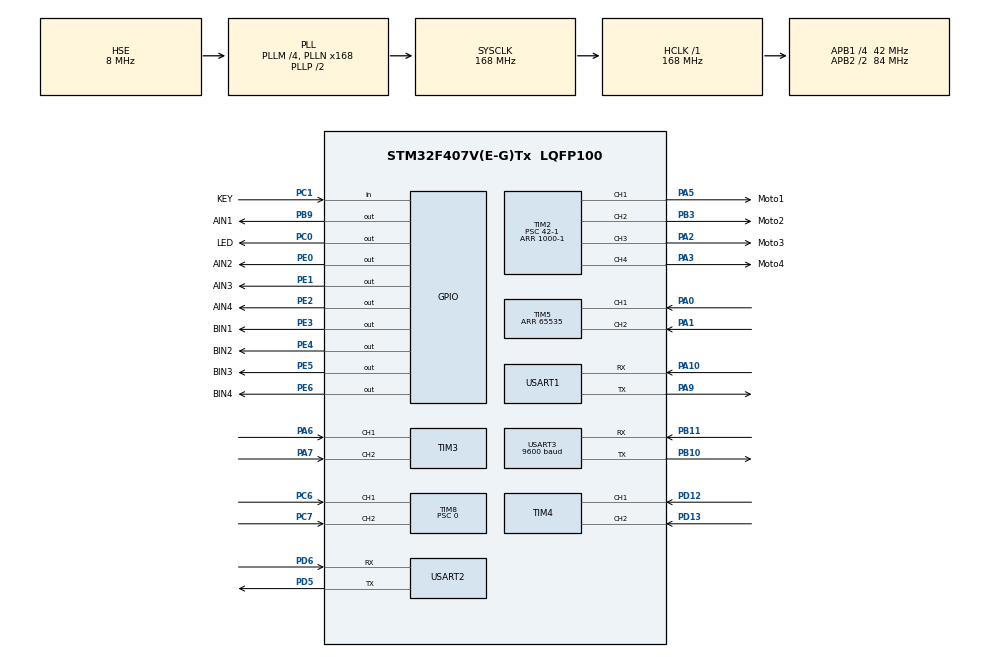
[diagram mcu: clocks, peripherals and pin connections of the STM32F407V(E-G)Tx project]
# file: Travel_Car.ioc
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Mcu.Family=STM32F4
Mcu.Name=STM32F407V(E-G)Tx
Mcu.Package=LQFP100
NVIC.PriorityGroup=NVIC_PRIORITYGROUP_4
NVIC.TIM1_UP_TIM10_IRQn=true\:0\:0\:false\:false\:true\:true\:true
NVIC.TIM2_IRQn=true\:0\:0\:false\:false\:true\:true\:true
NVIC.TIM3_IRQn=true\:0\:0\:false\:false\:true\:true\:true
NVIC.TIM4_IRQn=true\:0\:0\:false\:false\:true\:true\:true
NVIC.TIM5_IRQn=true\:0\:0\:false\:false\:true\:true\:true
NVIC.TIM8_UP_TIM13_IRQn=true\:0\:0\:false\:false\:true\:true\:true
NVIC.USART1_IRQn=true\:0\:0\:false\:false\:true\:true\:true
NVIC.USART2_IRQn=true\:0\:0\:false\:false\:true\:true\:true
NVIC.USART3_IRQn=true\:0\:0\:false\:false\:true\:true\:true
PA0-WKUP.Signal=S_TIM5_CH1
PA1.Signal=S_TIM5_CH2
PA10.Mode=Asynchronous
PA10.Signal=USART1_RX
PA13.Mode=Serial_Wire
PA13.Signal=SYS_JTMS-SWDIO
PA14.Mode=Serial_Wire
PA14.Signal=SYS_JTCK-SWCLK
PA2.GPIO_Label=Moto3
PA2.Signal=S_TIM2_CH3
PA3.GPIO_Label=Moto4
PA3.Signal=S_TIM2_CH4
PA5.GPIO_Label=Moto1
PA5.Signal=S_TIM2_CH1_ETR
PA6.Signal=S_TIM3_CH1
PA7.Signal=S_TIM3_CH2
PA9.Mode=Asynchronous
PA9.Signal=USART1_TX
PB10.Mode=Asynchronous
PB10.Signal=USART3_TX
PB11.Mode=Asynchronous
PB11.Signal=USART3_RX
PB3.GPIO_Label=Moto2
PB3.Signal=S_TIM2_CH2
PB9.GPIO_Label=AIN1
PB9.Signal=GPIO_Output
PC0.GPIO_Label=LED
PC0.Signal=GPIO_Output
PC1.GPIO_Label=KEY
PC1.GPIO_PuPd=GPIO_PULLUP
PC1.Signal=GPIO_Input
PC6.Signal=S_TIM8_CH1
PC7.Signal=S_TIM8_CH2
PD12.Signal=S_TIM4_CH1
PD13.Signal=S_TIM4_CH2
PD5.Mode=Asynchronous
PD5.Signal=USART2_TX
PD6.Mode=Asynchronous
PD6.Signal=USART2_RX
PE0.GPIO_Label=AIN2
PE0.Signal=GPIO_Output
PE1.GPIO_Label=AIN3
PE1.Signal=GPIO_Output
PE2.GPIO_Label=AIN4
PE2.Signal=GPIO_Output
PE3.GPIO_Label=BIN1
PE3.Signal=GPIO_Output
PE4.GPIO_Label=BIN2
PE4.Signal=GPIO_Output
PE5.GPIO_Label=BIN3
PE5.Signal=GPIO_Output
PE6.GPIO_Label=BIN4
PE6.Signal=GPIO_Output
PH0-OSC_IN.Mode=HSE-External-Oscillator
PH0-OSC_IN.Signal=RCC_OSC_IN
PH1-OSC_OUT.Mode=HSE-External-Oscillator
PH1-OSC_OUT.Signal=RCC_OSC_OUT
ProjectManager.HeapSize=0x200
ProjectManager.StackSize=0x400
ProjectManager.TargetToolchain=MDK-ARM V5.27
RCC.48MHZClocksFreq_Value=84000000
RCC.AHBFreq_Value=168000000
RCC.APB1CLKDivider=RCC_HCLK_DIV4
RCC.APB1Freq_Value=42000000
RCC.APB1TimFreq_Value=84000000
RCC.APB2CLKDivider=RCC_HCLK_DIV2
RCC.APB2Freq_Value=84000000
RCC.APB2TimFreq_Value=168000000
RCC.CortexFreq_Value=168000000
RCC.HCLKFreq_Value=168000000
RCC.HSE_VALUE=8000000
RCC.HSI_VALUE=16000000
RCC.LSE_VALUE=32768
RCC.PLLM=4
RCC.PLLN=168
RCC.PLLSourceVirtual=RCC_PLLSOURCE_HSE
RCC.SYSCLKFreq_VALUE=168000000
RCC.SYSCLKSource=RCC_SYSCLKSOURCE_PLLCLK
RCC.VCOOutputFreq_Value=336000000
SH.S_TIM2_CH1_ETR.0=TIM2_CH1,PWM Generation1 CH1
SH.S_TIM2_CH2.0=TIM2_CH2,PWM Generation2 CH2
SH.S_TIM2_CH3.0=TIM2_CH3,PWM Generation3 CH3
SH.S_TIM2_CH4.0=TIM2_CH4,PWM Generation4 CH4
SH.S_TIM3_CH1.0=TIM3_CH1,Encoder_Interface
SH.S_TIM3_CH2.0=TIM3_CH2,Encoder_Interface
SH.S_TIM4_CH1.0=TIM4_CH1,Encoder_Interface
SH.S_TIM4_CH2.0=TIM4_CH2,Encoder_Interface
SH.S_TIM5_CH1.0=TIM5_CH1,Encoder_Interface
SH.S_TIM5_CH2.0=TIM5_CH2,Encoder_Interface
SH.S_TIM8_CH1.0=TIM8_CH1,Encoder_Interface
SH.S_TIM8_CH2.0=TIM8_CH2,Encoder_Interface
TIM10.AutoReloadPreload=TIM_AUTORELOAD_PRELOAD_ENABLE
TIM10.Period=100-1
TIM10.Prescaler=168-1
TIM2.AutoReloadPreload=TIM_AUTORELOAD_PRELOAD_ENABLE
TIM2.Channel-PWM\ Generation1\ CH1=TIM_CHANNEL_1
TIM2.Channel-PWM\ Generation2\ CH2=TIM_CHANNEL_2
TIM2.Channel-PWM\ Generation3\ CH3=TIM_CHANNEL_3
TIM2.Channel-PWM\ Generation4\ CH4=TIM_CHANNEL_4
TIM2.Period=1000-1
TIM2.Prescaler=42-1
TIM3.AutoReloadPreload=TIM_AUTORELOAD_PRELOAD_ENABLE
TIM3.EncoderMode=TIM_ENCODERMODE_TI12
TIM4.AutoReloadPreload=TIM_AUTORELOAD_PRELOAD_ENABLE
TIM4.EncoderMode=TIM_ENCODERMODE_TI12
TIM5.AutoReloadPreload=TIM_AUTORELOAD_PRELOAD_ENABLE
TIM5.EncoderMode=TIM_ENCODERMODE_TI12
TIM5.Period=65535
TIM8.AutoReloadPreload=TIM_AUTORELOAD_PRELOAD_ENABLE
TIM8.EncoderMode=TIM_ENCODERMODE_TI12
TIM8.Period=65535
TIM8.Prescaler=0
USART1.VirtualMode=VM_ASYNC
USART2.VirtualMode=VM_ASYNC
USART3.BaudRate=9600
USART3.VirtualMode=VM_ASYNC
VP_TIM10_VS_ClockSourceINT.Mode=Enable_Timer
VP_TIM2_VS_ClockSourceINT.Mode=Internal
board=custom

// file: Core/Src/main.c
/* USER CODE BEGIN Header */
/**
  ******************************************************************************
  * @file           : main.c
  * @brief          : Main program body
  ******************************************************************************
  * @attention
  *
  * <h2><center>&copy; Copyright (c) 2020 STMicroelectronics.
  * All rights reserved.</center></h2>
  *
  * This software component is licensed by ST under BSD 3-Clause license,
  * the "License"; You may not use this file except in compliance with the
  * License. You may obtain a copy of the License at:
  *                        opensource.org/licenses/BSD-3-Clause
  *
  ******************************************************************************
  */
/* USER CODE END Header */
#include "main.h"
#include "tim.h"
#include "usart.h"
#include "gpio.h"

/* USER CODE BEGIN Includes */
#include "sensor8.h"
#include "Printf.h"
#include "led.h"
/* USER CODE END Includes */

/* USER CODE BEGIN PV */
int Usart_Received[3]={0};
/* USER CODE END PV */

void SystemClock_Config(void);

int main(void)
{

  /* MCU Configuration--------------------------------------------------------*/

  /* Reset of all peripherals, Initializes the Flash interface and the Systick. */
  HAL_Init();

  /* Configure the system clock */
  SystemClock_Config();

  /* Initialize all configured peripherals */
  MX_GPIO_Init();
  MX_USART1_UART_Init();
  MX_USART2_UART_Init();
  MX_USART3_UART_Init();
  MX_TIM2_Init();
  MX_TIM3_Init();
  MX_TIM8_Init();
  MX_TIM4_Init();
  MX_TIM5_Init();
  MX_TIM10_Init();
  /* USER CODE BEGIN 2 */
	Sensor_Init();
  /* USER CODE END 2 */

  /* Infinite loop */
  /* USER CODE BEGIN WHILE */
  while (1)
  {
		HAL_Delay(50);
		Led_Flash(10);
		Read_Data(Usart_Received);
    /* USER CODE END WHILE */

  }
}

void SystemClock_Config(void)
{
  RCC_OscInitTypeDef RCC_OscInitStruct = {0};
  RCC_ClkInitTypeDef RCC_ClkInitStruct = {0};

  /** Configure the main internal regulator output voltage
  */
  __HAL_RCC_PWR_CLK_ENABLE();
  __HAL_PWR_VOLTAGESCALING_CONFIG(PWR_REGULATOR_VOLTAGE_SCALE1);
  /** Initializes the RCC Oscillators according to the specified parameters
  * in the RCC_OscInitTypeDef structure.
  */
  RCC_OscInitStruct.OscillatorType = RCC_OSCILLATORTYPE_HSE;
  RCC_OscInitStruct.HSEState = RCC_HSE_ON;
  RCC_OscInitStruct.PLL.PLLState = RCC_PLL_ON;
  RCC_OscInitStruct.PLL.PLLSource = RCC_PLLSOURCE_HSE;
  RCC_OscInitStruct.PLL.PLLM = 4;
  RCC_OscInitStruct.PLL.PLLN = 168;
  RCC_OscInitStruct.PLL.PLLP = RCC_PLLP_DIV2;
  RCC_OscInitStruct.PLL.PLLQ = 4;
  if (HAL_RCC_OscConfig(&RCC_OscInitStruct) != HAL_OK)
  {
    Error_Handler();
  }
  /** Initializes the CPU, AHB and APB buses clocks
  */
  RCC_ClkInitStruct.ClockType = RCC_CLOCKTYPE_HCLK|RCC_CLOCKTYPE_SYSCLK
                              |RCC_CLOCKTYPE_PCLK1|RCC_CLOCKTYPE_PCLK2;
  RCC_ClkInitStruct.SYSCLKSource = RCC_SYSCLKSOURCE_PLLCLK;
  RCC_ClkInitStruct.AHBCLKDivider = RCC_SYSCLK_DIV1;
  RCC_ClkInitStruct.APB1CLKDivider = RCC_HCLK_DIV4;
  RCC_ClkInitStruct.APB2CLKDivider = RCC_HCLK_DIV2;

  if (HAL_RCC_ClockConfig(&RCC_ClkInitStruct, FLASH_LATENCY_5) != HAL_OK)
  {
    Error_Handler();
  }
}

void Error_Handler(void)
{
}

/************************ (C) COPYRIGHT STMicroelectronics *****END OF FILE****/
